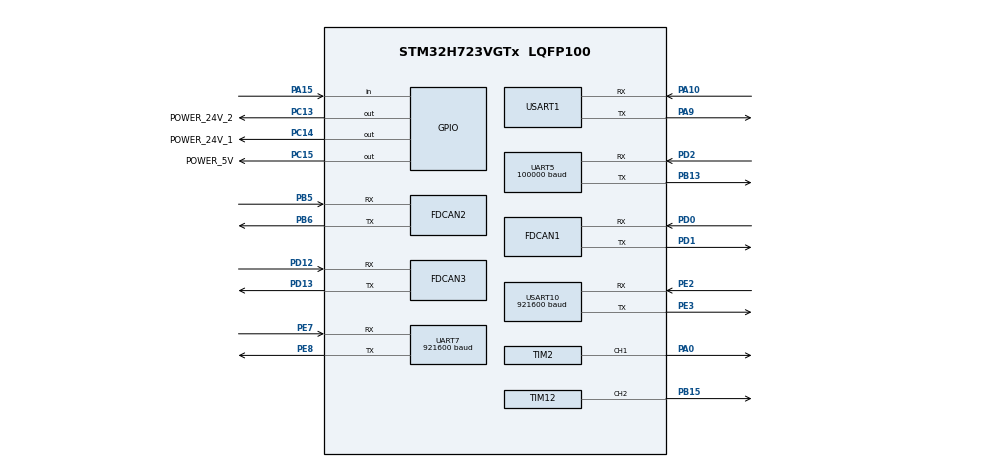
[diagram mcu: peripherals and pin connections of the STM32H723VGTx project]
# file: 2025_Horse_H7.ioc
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CORTEX_M7.AccessPermission-Cortex_Memory_Protection_Unit_Region2_Settings=MPU_REGION_FULL_ACCESS
CORTEX_M7.AccessPermission_S-Cortex_Memory_Protection_Unit_Region1_Settings_S=MPU_REGION_FULL_ACCESS
CORTEX_M7.AccessPermission_S-Cortex_Memory_Protection_Unit_Region2_Settings_S=MPU_REGION_FULL_ACCESS
CORTEX_M7.AccessPermission_S-Cortex_Memory_Protection_Unit_Region3_Settings_S=MPU_REGION_FULL_ACCESS
CORTEX_M7.AccessPermission_S-Cortex_Memory_Protection_Unit_Region4_Settings_S=MPU_REGION_FULL_ACCESS
CORTEX_M7.AccessPermission_S-Cortex_Memory_Protection_Unit_Region5_Settings_S=MPU_REGION_FULL_ACCESS
CORTEX_M7.AccessPermission_Spec=MPU_REGION_FULL_ACCESS
CORTEX_M7.BaseAddress-Cortex_Memory_Protection_Unit_Region2_Settings=0x24000000
CORTEX_M7.BaseAddress_S-Cortex_Memory_Protection_Unit_Region1_Settings_S=0x60000000
CORTEX_M7.BaseAddress_S-Cortex_Memory_Protection_Unit_Region2_Settings_S=0x30000000
CORTEX_M7.BaseAddress_S-Cortex_Memory_Protection_Unit_Region3_Settings_S=0x30020000
CORTEX_M7.BaseAddress_S-Cortex_Memory_Protection_Unit_Region4_Settings_S=0x30040000
CORTEX_M7.BaseAddress_S-Cortex_Memory_Protection_Unit_Region5_Settings_S=0x3800000
CORTEX_M7.BaseAddress_Spec=0x24000000
CORTEX_M7.CPU_DCache=Disabled
CORTEX_M7.CPU_ICache=Disabled
CORTEX_M7.DisableExec_Spec=MPU_INSTRUCTION_ACCESS_ENABLE
CORTEX_M7.Enable-Cortex_Memory_Protection_Unit_Region2_Settings=MPU_REGION_ENABLE
CORTEX_M7.Enable_S-Cortex_Memory_Protection_Unit_Region1_Settings_S=MPU_REGION_ENABLE
CORTEX_M7.Enable_S-Cortex_Memory_Protection_Unit_Region2_Settings_S=MPU_REGION_ENABLE
CORTEX_M7.Enable_S-Cortex_Memory_Protection_Unit_Region3_Settings_S=MPU_REGION_ENABLE
CORTEX_M7.Enable_S-Cortex_Memory_Protection_Unit_Region4_Settings_S=MPU_REGION_ENABLE
CORTEX_M7.Enable_S-Cortex_Memory_Protection_Unit_Region5_Settings_S=MPU_REGION_ENABLE
CORTEX_M7.IsBufferable_S-Cortex_Memory_Protection_Unit_Region1_Settings_S=MPU_ACCESS_BUFFERABLE
CORTEX_M7.IsBufferable_Spec=MPU_ACCESS_BUFFERABLE
CORTEX_M7.IsCacheable-Cortex_Memory_Protection_Unit_Region2_Settings=MPU_ACCESS_NOT_CACHEABLE
CORTEX_M7.IsCacheable_S-Cortex_Memory_Protection_Unit_Region2_Settings_S=MPU_ACCESS_CACHEABLE
CORTEX_M7.IsCacheable_S-Cortex_Memory_Protection_Unit_Region3_Settings_S=MPU_ACCESS_CACHEABLE
CORTEX_M7.IsCacheable_S-Cortex_Memory_Protection_Unit_Region4_Settings_S=MPU_ACCESS_CACHEABLE
CORTEX_M7.IsCacheable_S-Cortex_Memory_Protection_Unit_Region5_Settings_S=MPU_ACCESS_CACHEABLE
CORTEX_M7.IsCacheable_Spec=MPU_ACCESS_CACHEABLE
CORTEX_M7.IsShareable-Cortex_Memory_Protection_Unit_Region2_Settings=MPU_ACCESS_NOT_SHAREABLE
CORTEX_M7.IsShareable_Spec=MPU_ACCESS_NOT_SHAREABLE
CORTEX_M7.MPU_Control=__NULL
CORTEX_M7.Size-Cortex_Memory_Protection_Unit_Region2_Settings=MPU_REGION_SIZE_512KB
CORTEX_M7.Size_S-Cortex_Memory_Protection_Unit_Region1_Settings_S=MPU_REGION_SIZE_64KB
CORTEX_M7.Size_S-Cortex_Memory_Protection_Unit_Region2_Settings_S=MPU_REGION_SIZE_128KB
CORTEX_M7.Size_S-Cortex_Memory_Protection_Unit_Region3_Settings_S=MPU_REGION_SIZE_128KB
CORTEX_M7.Size_S-Cortex_Memory_Protection_Unit_Region4_Settings_S=MPU_REGION_SIZE_32KB
CORTEX_M7.Size_S-Cortex_Memory_Protection_Unit_Region5_Settings_S=MPU_REGION_SIZE_64KB
CORTEX_M7.Size_Spec=MPU_REGION_SIZE_512KB
CORTEX_M7.SubRegionDisable_Spec=0x0
CORTEX_M7.default_mode_Activation=0
Dma.Request0=USART10_RX
Dma.Request1=USART10_TX
Dma.Request2=USART1_RX
Dma.Request3=USART1_TX
Dma.Request4=UART7_RX
Dma.Request5=UART7_TX
Dma.Request6=UART5_RX
Dma.UART5_RX.6.Direction=DMA_PERIPH_TO_MEMORY
Dma.UART5_RX.6.EventEnable=DISABLE
Dma.UART5_RX.6.FIFOMode=DMA_FIFOMODE_DISABLE
Dma.UART5_RX.6.Instance=DMA1_Stream2
Dma.UART5_RX.6.MemDataAlignment=DMA_MDATAALIGN_BYTE
Dma.UART5_RX.6.MemInc=DMA_MINC_ENABLE
Dma.UART5_RX.6.Mode=DMA_NORMAL
Dma.UART5_RX.6.PeriphDataAlignment=DMA_PDATAALIGN_BYTE
Dma.UART5_RX.6.PeriphInc=DMA_PINC_DISABLE
Dma.UART5_RX.6.Polarity=HAL_DMAMUX_REQ_GEN_RISING
Dma.UART5_RX.6.Priority=DMA_PRIORITY_HIGH
Dma.UART5_RX.6.RequestNumber=1
Dma.UART5_RX.6.SignalID=NONE
Dma.UART5_RX.6.SyncEnable=DISABLE
Dma.UART5_RX.6.SyncPolarity=HAL_DMAMUX_SYNC_NO_EVENT
Dma.UART5_RX.6.SyncRequestNumber=1
Dma.UART5_RX.6.SyncSignalID=NONE
Dma.UART7_RX.4.Direction=DMA_PERIPH_TO_MEMORY
Dma.UART7_RX.4.EventEnable=DISABLE
Dma.UART7_RX.4.FIFOMode=DMA_FIFOMODE_DISABLE
Dma.UART7_RX.4.Instance=DMA2_Stream4
Dma.UART7_RX.4.MemDataAlignment=DMA_MDATAALIGN_BYTE
Dma.UART7_RX.4.MemInc=DMA_MINC_ENABLE
Dma.UART7_RX.4.Mode=DMA_NORMAL
Dma.UART7_RX.4.PeriphDataAlignment=DMA_PDATAALIGN_BYTE
Dma.UART7_RX.4.PeriphInc=DMA_PINC_DISABLE
Dma.UART7_RX.4.Polarity=HAL_DMAMUX_REQ_GEN_RISING
Dma.UART7_RX.4.Priority=DMA_PRIORITY_HIGH
Dma.UART7_RX.4.RequestNumber=1
Dma.UART7_RX.4.SignalID=NONE
Dma.UART7_RX.4.SyncEnable=DISABLE
Dma.UART7_RX.4.SyncPolarity=HAL_DMAMUX_SYNC_NO_EVENT
Dma.UART7_RX.4.SyncRequestNumber=1
Dma.UART7_RX.4.SyncSignalID=NONE
Dma.UART7_TX.5.Direction=DMA_MEMORY_TO_PERIPH
Dma.UART7_TX.5.EventEnable=DISABLE
Dma.UART7_TX.5.FIFOMode=DMA_FIFOMODE_DISABLE
Dma.UART7_TX.5.Instance=DMA1_Stream3
Dma.UART7_TX.5.MemDataAlignment=DMA_MDATAALIGN_BYTE
Dma.UART7_TX.5.MemInc=DMA_MINC_ENABLE
Dma.UART7_TX.5.Mode=DMA_NORMAL
Dma.UART7_TX.5.PeriphDataAlignment=DMA_PDATAALIGN_BYTE
Dma.UART7_TX.5.PeriphInc=DMA_PINC_DISABLE
Dma.UART7_TX.5.Polarity=HAL_DMAMUX_REQ_GEN_RISING
Dma.UART7_TX.5.Priority=DMA_PRIORITY_HIGH
Dma.UART7_TX.5.RequestNumber=1
Dma.UART7_TX.5.SignalID=NONE
Dma.UART7_TX.5.SyncEnable=DISABLE
Dma.UART7_TX.5.SyncPolarity=HAL_DMAMUX_SYNC_NO_EVENT
Dma.UART7_TX.5.SyncRequestNumber=1
Dma.UART7_TX.5.SyncSignalID=NONE
Dma.USART10_RX.0.Direction=DMA_PERIPH_TO_MEMORY
Dma.USART10_RX.0.EventEnable=DISABLE
Dma.USART10_RX.0.FIFOMode=DMA_FIFOMODE_DISABLE
Dma.USART10_RX.0.Instance=DMA2_Stream7
Dma.USART10_RX.0.MemDataAlignment=DMA_MDATAALIGN_BYTE
Dma.USART10_RX.0.MemInc=DMA_MINC_ENABLE
Dma.USART10_RX.0.Mode=DMA_NORMAL
Dma.USART10_RX.0.PeriphDataAlignment=DMA_PDATAALIGN_BYTE
Dma.USART10_RX.0.PeriphInc=DMA_PINC_DISABLE
Dma.USART10_RX.0.Polarity=HAL_DMAMUX_REQ_GEN_RISING
Dma.USART10_RX.0.Priority=DMA_PRIORITY_VERY_HIGH
Dma.USART10_RX.0.RequestNumber=1
Dma.USART10_RX.0.SignalID=NONE
Dma.USART10_RX.0.SyncEnable=DISABLE
Dma.USART10_RX.0.SyncPolarity=HAL_DMAMUX_SYNC_NO_EVENT
Dma.USART10_RX.0.SyncRequestNumber=1
Dma.USART10_RX.0.SyncSignalID=NONE
Dma.USART10_TX.1.Direction=DMA_MEMORY_TO_PERIPH
Dma.USART10_TX.1.EventEnable=DISABLE
Dma.USART10_TX.1.FIFOMode=DMA_FIFOMODE_DISABLE
Dma.USART10_TX.1.Instance=DMA2_Stream3
Dma.USART10_TX.1.MemDataAlignment=DMA_MDATAALIGN_BYTE
Dma.USART10_TX.1.MemInc=DMA_MINC_ENABLE
Dma.USART10_TX.1.Mode=DMA_NORMAL
Dma.USART10_TX.1.PeriphDataAlignment=DMA_PDATAALIGN_BYTE
Dma.USART10_TX.1.PeriphInc=DMA_PINC_DISABLE
Dma.USART10_TX.1.Polarity=HAL_DMAMUX_REQ_GEN_RISING
Dma.USART10_TX.1.Priority=DMA_PRIORITY_LOW
Dma.USART10_TX.1.RequestNumber=1
Dma.USART10_TX.1.SignalID=NONE
Dma.USART10_TX.1.SyncEnable=DISABLE
Dma.USART10_TX.1.SyncPolarity=HAL_DMAMUX_SYNC_NO_EVENT
Dma.USART10_TX.1.SyncRequestNumber=1
Dma.USART10_TX.1.SyncSignalID=NONE
Dma.USART1_RX.2.Direction=DMA_PERIPH_TO_MEMORY
Dma.USART1_RX.2.EventEnable=DISABLE
Dma.USART1_RX.2.FIFOMode=DMA_FIFOMODE_DISABLE
Dma.USART1_RX.2.Instance=DMA1_Stream0
Dma.USART1_RX.2.MemDataAlignment=DMA_MDATAALIGN_BYTE
Dma.USART1_RX.2.MemInc=DMA_MINC_ENABLE
Dma.USART1_RX.2.Mode=DMA_NORMAL
Dma.USART1_RX.2.PeriphDataAlignment=DMA_PDATAALIGN_BYTE
Dma.USART1_RX.2.PeriphInc=DMA_PINC_DISABLE
Dma.USART1_RX.2.Polarity=HAL_DMAMUX_REQ_GEN_RISING
Dma.USART1_RX.2.Priority=DMA_PRIORITY_HIGH
Dma.USART1_RX.2.RequestNumber=1
Dma.USART1_RX.2.SignalID=NONE
Dma.USART1_RX.2.SyncEnable=DISABLE
Dma.USART1_RX.2.SyncPolarity=HAL_DMAMUX_SYNC_NO_EVENT
Dma.USART1_RX.2.SyncRequestNumber=1
Dma.USART1_RX.2.SyncSignalID=NONE
Dma.USART1_TX.3.Direction=DMA_MEMORY_TO_PERIPH
Dma.USART1_TX.3.EventEnable=DISABLE
Dma.USART1_TX.3.FIFOMode=DMA_FIFOMODE_DISABLE
Dma.USART1_TX.3.Instance=DMA1_Stream1
Dma.USART1_TX.3.MemDataAlignment=DMA_MDATAALIGN_BYTE
Dma.USART1_TX.3.MemInc=DMA_MINC_ENABLE
Dma.USART1_TX.3.Mode=DMA_NORMAL
Dma.USART1_TX.3.PeriphDataAlignment=DMA_PDATAALIGN_BYTE
Dma.USART1_TX.3.PeriphInc=DMA_PINC_DISABLE
Dma.USART1_TX.3.Polarity=HAL_DMAMUX_REQ_GEN_RISING
Dma.USART1_TX.3.Priority=DMA_PRIORITY_LOW
Dma.USART1_TX.3.RequestNumber=1
Dma.USART1_TX.3.SignalID=NONE
Dma.USART1_TX.3.SyncEnable=DISABLE
Dma.USART1_TX.3.SyncPolarity=HAL_DMAMUX_SYNC_NO_EVENT
Dma.USART1_TX.3.SyncRequestNumber=1
Dma.USART1_TX.3.SyncSignalID=NONE
FDCAN1.CalculateBaudRateNominal=1000000
FDCAN1.CalculateTimeBitNominal=1000
FDCAN1.CalculateTimeQuantumNominal=25.0
FDCAN1.DataPrescaler=3
FDCAN1.DataSyncJumpWidth=10
FDCAN1.DataTimeSeg1=29
FDCAN1.DataTimeSeg2=10
FDCAN1.NominalPrescaler=3
FDCAN1.NominalSyncJumpWidth=10
FDCAN1.NominalTimeSeg1=29
FDCAN1.NominalTimeSeg2=10
FDCAN1.RxFifo0ElmtsNbr=32
FDCAN1.RxFifo1ElmtsNbr=32
FDCAN1.StdFiltersNbr=1
FDCAN1.TxFifoQueueElmtsNbr=32
FDCAN2.CalculateBaudRateNominal=1000000
FDCAN2.CalculateTimeBitNominal=1000
FDCAN2.CalculateTimeQuantumNominal=25.0
FDCAN2.DataPrescaler=3
FDCAN2.DataSyncJumpWidth=10
FDCAN2.DataTimeSeg1=29
FDCAN2.DataTimeSeg2=10
FDCAN2.MessageRAMOffset=0x406
FDCAN2.NominalPrescaler=3
FDCAN2.NominalSyncJumpWidth=10
FDCAN2.NominalTimeSeg1=29
FDCAN2.NominalTimeSeg2=10
FDCAN2.RxFifo0ElmtsNbr=32
FDCAN2.RxFifo1ElmtsNbr=32
FDCAN2.StdFiltersNbr=1
FDCAN2.TxFifoQueueElmtsNbr=32
FDCAN3.CalculateBaudRateNominal=1000000
FDCAN3.CalculateTimeBitNominal=1000
FDCAN3.CalculateTimeQuantumNominal=25.0
FDCAN3.DataPrescaler=3
FDCAN3.DataSyncJumpWidth=10
FDCAN3.DataTimeSeg1=29
FDCAN3.DataTimeSeg2=10
FDCAN3.MessageRAMOffset=0x812
FDCAN3.NominalPrescaler=3
FDCAN3.NominalSyncJumpWidth=10
FDCAN3.NominalTimeSeg1=29
FDCAN3.NominalTimeSeg2=10
FDCAN3.RxFifo0ElmtsNbr=32
FDCAN3.RxFifo1ElmtsNbr=32
FDCAN3.StdFiltersNbr=1
FDCAN3.TxEventsNbr=0
FDCAN3.TxFifoQueueElmtsNbr=32
FREERTOS.Tasks01=Vofa_Receive,24,128,VofaReceiveTask,As weak,NULL,Dynamic,NULL,NULL;UART_TX,40,512,UART_TX_task,As weak,NULL,Dynamic,NULL,NULL
FREERTOS.configUSE_NEWLIB_REENTRANT=1
Mcu.Family=STM32H7
Mcu.Name=STM32H723VGTx
Mcu.Package=LQFP100
NVIC.DMA1_Stream0_IRQn=true\:0\:0\:true\:false\:true\:false\:false\:true\:true
NVIC.DMA1_Stream1_IRQn=true\:0\:0\:true\:false\:true\:false\:false\:true\:true
NVIC.DMA1_Stream2_IRQn=true\:5\:0\:false\:false\:true\:false\:false\:true\:true
NVIC.DMA1_Stream3_IRQn=true\:0\:0\:true\:false\:true\:false\:false\:true\:true
NVIC.DMA2_Stream3_IRQn=true\:0\:0\:true\:false\:true\:false\:false\:true\:true
NVIC.DMA2_Stream4_IRQn=true\:0\:0\:true\:false\:true\:false\:false\:true\:true
NVIC.DMA2_Stream7_IRQn=true\:0\:0\:true\:false\:true\:false\:false\:true\:true
NVIC.FDCAN1_IT0_IRQn=true\:0\:0\:false\:false\:true\:false\:true\:true\:true
NVIC.FDCAN1_IT1_IRQn=true\:0\:0\:false\:false\:true\:false\:true\:true\:true
NVIC.FDCAN2_IT0_IRQn=true\:0\:0\:false\:false\:true\:false\:true\:true\:true
NVIC.FDCAN2_IT1_IRQn=true\:0\:0\:true\:false\:true\:false\:true\:true\:true
NVIC.FDCAN3_IT0_IRQn=true\:0\:0\:false\:false\:true\:false\:true\:true\:true
NVIC.FDCAN3_IT1_IRQn=true\:0\:0\:false\:false\:true\:false\:true\:true\:true
NVIC.PriorityGroup=NVIC_PRIORITYGROUP_4
NVIC.TIM2_IRQn=true\:5\:0\:false\:false\:true\:true\:true\:true\:true
NVIC.TIM4_IRQn=true\:15\:0\:false\:false\:true\:false\:false\:true\:true
NVIC.TIM6_DAC_IRQn=true\:5\:0\:false\:false\:true\:true\:true\:true\:true
NVIC.TimeBase=TIM4_IRQn
NVIC.TimeBaseIP=TIM4
NVIC.UART5_IRQn=true\:5\:0\:false\:false\:true\:true\:true\:true\:true
NVIC.UART7_IRQn=true\:5\:0\:false\:false\:true\:true\:true\:true\:true
NVIC.USART10_IRQn=true\:5\:0\:false\:false\:true\:true\:true\:true\:true
NVIC.USART1_IRQn=true\:5\:0\:false\:false\:true\:true\:true\:true\:true
PA0.Signal=S_TIM2_CH1_ETR
PA10.Mode=Asynchronous
PA10.Signal=USART1_RX
PA11.Signal=USB_OTG_HS_DM
PA12.Signal=USB_OTG_HS_DP
PA13(JTMS/SWDIO).Mode=Serial_Wire
PA13(JTMS/SWDIO).Signal=DEBUG_JTMS-SWDIO
PA14(JTCK/SWCLK).Mode=Serial_Wire
PA14(JTCK/SWCLK).Signal=DEBUG_JTCK-SWCLK
PA15(JTDI).Signal=GPIO_Input
PA9.Mode=Asynchronous
PA9.Signal=USART1_TX
PB13.Mode=Asynchronous
PB13.Signal=UART5_TX
PB15.Signal=S_TIM12_CH2
PB5.Mode=FDCAN_Activate
PB5.Signal=FDCAN2_RX
PB6.Mode=FDCAN_Activate
PB6.Signal=FDCAN2_TX
PC13.GPIO_Label=POWER_24V_2
PC13.PinState=GPIO_PIN_SET
PC13.Signal=GPIO_Output
PC14-OSC32_IN.GPIO_Label=POWER_24V_1
PC14-OSC32_IN.PinState=GPIO_PIN_SET
PC14-OSC32_IN.Signal=GPIO_Output
PC15-OSC32_OUT.GPIO_Label=POWER_5V
PC15-OSC32_OUT.PinState=GPIO_PIN_SET
PC15-OSC32_OUT.Signal=GPIO_Output
PD0.Mode=FDCAN_Activate
PD0.Signal=FDCAN1_RX
PD1.Mode=FDCAN_Activate
PD1.Signal=FDCAN1_TX
PD12.Mode=FDCAN_Activate
PD12.Signal=FDCAN3_RX
PD13.Mode=FDCAN_Activate
PD13.Signal=FDCAN3_TX
PD2.Mode=Asynchronous
PD2.Signal=UART5_RX
PE2.Mode=Asynchronous
PE2.Signal=USART10_RX
PE3.Mode=Asynchronous
PE3.Signal=USART10_TX
PE7.Mode=Asynchronous
PE7.Signal=UART7_RX
PE8.Mode=Asynchronous
PE8.Signal=UART7_TX
PH0-OSC_IN.Mode=HSE-External-Oscillator
PH0-OSC_IN.Signal=RCC_OSC_IN
PH1-OSC_OUT.Mode=HSE-External-Oscillator
PH1-OSC_OUT.Signal=RCC_OSC_OUT
ProjectManager.HeapSize=0x200
ProjectManager.StackSize=0x400
ProjectManager.TargetToolchain=STM32CubeIDE
RCC.ADCFreq_Value=48375000
RCC.APB1Freq_Value=120000000
RCC.APB2Freq_Value=120000000
RCC.APB3Freq_Value=120000000
RCC.APB4Freq_Value=120000000
RCC.CortexFreq_Value=480000000
RCC.D1PPRE=RCC_APB3_DIV2
RCC.D2PPRE1=RCC_APB1_DIV2
RCC.D2PPRE2=RCC_APB2_DIV2
RCC.D3PPRE=RCC_APB4_DIV2
RCC.DIVM1=2
RCC.DIVN1=40
RCC.DIVP1=1
RCC.DIVQ1=4
RCC.HCLKFreq_Value=240000000
RCC.HPRE=RCC_HCLK_DIV2
RCC.HSE_VALUE=24000000
RCC.PLL2FRACN=0
RCC.PLL2_VCI_Range-AdvancedSettings=RCC_PLL2VCIRANGE_0
RCC.PLL3FRACN=0
RCC.PLLFRACN=0
RCC.PLLSourceVirtual=RCC_PLLSOURCE_HSE
RCC.SYSCLKFreq_VALUE=480000000
RCC.SYSCLKSource=RCC_SYSCLKSOURCE_PLLCLK
RCC.USBFreq_Value=120000000
SH.S_TIM12_CH2.0=TIM12_CH2,PWM Generation2 CH2
SH.S_TIM2_CH1_ETR.0=TIM2_CH1,PWM Generation1 CH1
TIM12.AutoReloadPreload=TIM_AUTORELOAD_PRELOAD_ENABLE
TIM12.Channel-PWM\ Generation2\ CH2=TIM_CHANNEL_2
TIM12.Period=250-1
TIM12.Prescaler=240-1
TIM2.AutoReloadPreload=TIM_AUTORELOAD_PRELOAD_ENABLE
TIM2.Channel-PWM\ Generation1\ CH1=TIM_CHANNEL_1
TIM2.OCPolarity_1=TIM_OCPOLARITY_LOW
TIM2.Period=1000
TIM2.Prescaler=2400-1
TIM2.Pulse-PWM\ Generation1\ CH1=5000
TIM6.AutoReloadPreload=TIM_AUTORELOAD_PRELOAD_ENABLE
TIM6.Period=1000-1
TIM6.Prescaler=480-1
UART5.BaudRate=100000
UART5.Parity=PARITY_EVEN
UART5.StopBits=UART_STOPBITS_2
UART5.WordLength=WORDLENGTH_9B
UART7.BaudRate=921600
USART1.VirtualMode-Asynchronous=VM_ASYNC
USART10.BaudRate=921600
USART10.FIFOMode=FIFOMODE_DISABLE
USART10.RXFIFOThreshold=RXFIFO_THRESHOLD_1EIGHTHFULL
USART10.VirtualMode=VM_ASYNC
VP_FREERTOS_VS_CMSIS_V2.Mode=CMSIS_V2
VP_MEMORYMAP_VS_MEMORYMAP.Mode=CurAppReg
VP_SYS_VS_tim4.Mode=TIM4
VP_TIM2_VS_ClockSourceINT.Mode=Internal
VP_TIM6_VS_ClockSourceINT.Mode=Enable_Timer
board=custom

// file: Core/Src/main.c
/* USER CODE BEGIN Header */
/**
  ******************************************************************************
  * @file           : main.c
  * @brief          : Main program body
  ******************************************************************************
  * @attention
  *
  * Copyright (c) 2024 STMicroelectronics.
  * All rights reserved.
  *
  * This software is licensed under terms that can be found in the LICENSE file
  * in the root directory of this software component.
  * If no LICENSE file comes with this software, it is provided AS-IS.
  *
  ******************************************************************************
  */
/* USER CODE END Header */
#include "main.h"
#include "cmsis_os.h"
#include "dma.h"
#include "fdcan.h"
#include "memorymap.h"
#include "tim.h"
#include "usart.h"
#include "gpio.h"

/* USER CODE BEGIN Includes */

#include "UART_DMA.h"
#include "vofa.h"
#include "Cpp/Main.h"
#include "FDCAN_receive_dm.h"
#include "Cpp/Callback.h"
/* USER CODE END Includes */

void SystemClock_Config(void);
void MX_FREERTOS_Init(void);

int main(void)
{

  /* MCU Configuration--------------------------------------------------------*/

  /* Reset of all peripherals, Initializes the Flash interface and the Systick. */
  HAL_Init();

  /* Configure the system clock */
  SystemClock_Config();

  /* Initialize all configured peripherals */
  MX_GPIO_Init();
  MX_DMA_Init();
  MX_USART1_UART_Init();
  MX_USART10_UART_Init();
  MX_UART7_Init();
  MX_TIM6_Init();
  MX_TIM12_Init();
  MX_FDCAN1_Init();
  MX_FDCAN2_Init();
  MX_FDCAN3_Init();
  MX_TIM2_Init();
  MX_UART5_Init();
  /* USER CODE BEGIN 2 */
  Main();
  /* USER CODE END 2 */

  /* Init scheduler */
  osKernelInitialize();

  /* Call init function for freertos objects (in cmsis_os2.c) */
  MX_FREERTOS_Init();

  /* Start scheduler */
  osKernelStart();

  /* We should never get here as control is now taken by the scheduler */

  /* Infinite loop */
  while (1)
  {

  }
}

void SystemClock_Config(void)
{
  RCC_OscInitTypeDef RCC_OscInitStruct = {0};
  RCC_ClkInitTypeDef RCC_ClkInitStruct = {0};

  /** Supply configuration update enable
  */
  HAL_PWREx_ConfigSupply(PWR_LDO_SUPPLY);

  /** Configure the main internal regulator output voltage
  */
  __HAL_PWR_VOLTAGESCALING_CONFIG(PWR_REGULATOR_VOLTAGE_SCALE0);

  while(!__HAL_PWR_GET_FLAG(PWR_FLAG_VOSRDY)) {}

  /** Initializes the RCC Oscillators according to the specified parameters
  * in the RCC_OscInitTypeDef structure.
  */
  RCC_OscInitStruct.OscillatorType = RCC_OSCILLATORTYPE_HSE;
  RCC_OscInitStruct.HSEState = RCC_HSE_ON;
  RCC_OscInitStruct.PLL.PLLState = RCC_PLL_ON;
  RCC_OscInitStruct.PLL.PLLSource = RCC_PLLSOURCE_HSE;
  RCC_OscInitStruct.PLL.PLLM = 2;
  RCC_OscInitStruct.PLL.PLLN = 40;
  RCC_OscInitStruct.PLL.PLLP = 1;
  RCC_OscInitStruct.PLL.PLLQ = 4;
  RCC_OscInitStruct.PLL.PLLR = 2;
  RCC_OscInitStruct.PLL.PLLRGE = RCC_PLL1VCIRANGE_3;
  RCC_OscInitStruct.PLL.PLLVCOSEL = RCC_PLL1VCOWIDE;
  RCC_OscInitStruct.PLL.PLLFRACN = 0;
  if (HAL_RCC_OscConfig(&RCC_OscInitStruct) != HAL_OK)
  {
    Error_Handler();
  }

  /** Initializes the CPU, AHB and APB buses clocks
  */
  RCC_ClkInitStruct.ClockType = RCC_CLOCKTYPE_HCLK|RCC_CLOCKTYPE_SYSCLK
                              |RCC_CLOCKTYPE_PCLK1|RCC_CLOCKTYPE_PCLK2
                              |RCC_CLOCKTYPE_D3PCLK1|RCC_CLOCKTYPE_D1PCLK1;
  RCC_ClkInitStruct.SYSCLKSource = RCC_SYSCLKSOURCE_PLLCLK;
  RCC_ClkInitStruct.SYSCLKDivider = RCC_SYSCLK_DIV1;
  RCC_ClkInitStruct.AHBCLKDivider = RCC_HCLK_DIV2;
  RCC_ClkInitStruct.APB3CLKDivider = RCC_APB3_DIV2;
  RCC_ClkInitStruct.APB1CLKDivider = RCC_APB1_DIV2;
  RCC_ClkInitStruct.APB2CLKDivider = RCC_APB2_DIV2;
  RCC_ClkInitStruct.APB4CLKDivider = RCC_APB4_DIV2;

  if (HAL_RCC_ClockConfig(&RCC_ClkInitStruct, FLASH_LATENCY_3) != HAL_OK)
  {
    Error_Handler();
  }
}

void HAL_TIM_PeriodElapsedCallback(TIM_HandleTypeDef *htim)
{
  /* USER CODE BEGIN Callback 0 */
  if (htim->Instance == TIM6)
  {
    TIM6_CALLBACK();
  }
  /* USER CODE END Callback 0 */
  if (htim->Instance == TIM4)
  {
    HAL_IncTick();
  }
}

void Error_Handler(void)
{
  __disable_irq();
  while (1)
  {
  }
}

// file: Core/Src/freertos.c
/* USER CODE BEGIN Header */
/**
  ******************************************************************************
  * File Name          : freertos.c
  * Description        : Code for freertos applications
  ******************************************************************************
  * @attention
  *
  * Copyright (c) 2025 STMicroelectronics.
  * All rights reserved.
  *
  * This software is licensed under terms that can be found in the LICENSE file
  * in the root directory of this software component.
  * If no LICENSE file comes with this software, it is provided AS-IS.
  *
  ******************************************************************************
  */
/* USER CODE END Header */

#include "FreeRTOS.h"
#include "task.h"
#include "main.h"
#include "cmsis_os.h"

/* USER CODE BEGIN Includes */
#include "fdcan.h"
#include "FDCAN_receive_dm.h"
#include "UART_DMA.h"
#include "vofa.h"
#include "bsp_mc02/can_bsp.h"
/* USER CODE END Includes */

/* USER CODE BEGIN Variables */
extern motor_t motor[12];
/* USER CODE END Variables */
/* Definitions for Vofa_Receive */
osThreadId_t Vofa_ReceiveHandle;
const osThreadAttr_t Vofa_Receive_attributes = {
  .name = "Vofa_Receive",
  .stack_size = 128 * 4,
  .priority = (osPriority_t) osPriorityNormal,
};
/* Definitions for UART_TX */
osThreadId_t UART_TXHandle;
const osThreadAttr_t UART_TX_attributes = {
  .name = "UART_TX",
  .stack_size = 512 * 4,
  .priority = (osPriority_t) osPriorityHigh,
};

void VofaReceiveTask(void *argument);
void UART_TX_task(void *argument);

void MX_FREERTOS_Init(void); /* (MISRA C 2004 rule 8.1) */

void MX_FREERTOS_Init(void) {

  /* Create the thread(s) */
  /* creation of Vofa_Receive */
  Vofa_ReceiveHandle = osThreadNew(VofaReceiveTask, NULL, &Vofa_Receive_attributes);

  /* creation of UART_TX */
  UART_TXHandle = osThreadNew(UART_TX_task, NULL, &UART_TX_attributes);

}

__weak void VofaReceiveTask(void *argument)
{
  for(;;)
  {
    osDelay(1);
  }
}

__weak void UART_TX_task(void *argument)
{
  for(;;)
  {
    osDelay(1);
  }
}
